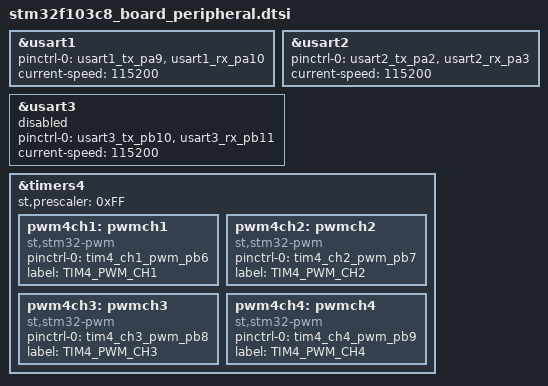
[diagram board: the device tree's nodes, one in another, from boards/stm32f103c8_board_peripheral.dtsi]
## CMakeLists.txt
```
# Author: Mohd Ramza <mohdramza@yahoo.com>
# SPDX-License-Identifier: Apache-2.0

cmake_minimum_required(VERSION 3.20.0)

set(BOARD_ROOT ${CMAKE_CURRENT_SOURCE_DIR})
set(BOARD com_f103c8)
set(CURR ${CMAKE_CURRENT_SOURCE_DIR})

list(APPEND DTC_OVERLAY_FILE ${CURR}/boards/stm32f103c8_board.overlay)
message(status ${DTC_OVERLAY_FILE})

# set(BOARD qemu_x86)
# set(BOARD_FLASH_RUNNER jlink)
find_package(Zephyr REQUIRED HINTS $ENV{ZEPHYR_BASE})
project(stm32f1_project)

# add top source files here
set(SOURCES src/main.c
)

# likely not need to add a .h include here as most modules will go into its own sub directory
set(INCLUDES)

target_include_directories(app PRIVATE ${INCLUDES})
target_sources(app PRIVATE ${SOURCES})

add_subdirectory(src/MANAGER/THREAD_MGR)
add_subdirectory(src/MANAGER/BLINK_MGR)

# Specific part for documentation sbuild. You should  provide -DBUILD_DOC=1 in CMake call to let it build documentation.
if(BUILD_DOC)
    include(doc/build_doxygen_documentation.cmake)
endif()
```

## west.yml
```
manifest:
  remotes:
    - name: zephyrproject-rtos
      url-base: https://github.com/zephyrproject-rtos
  projects:
    - name: zephyr
      remote: zephyrproject-rtos
      revision: zephyr-v3.1.0
      west-commands: scripts/west-commands.yml
      import:
        name-allowlist:
        - hal_st
        - hal_stm32
        - cmsis

  self:
    path: zephyr_stm32f1_minimal
```

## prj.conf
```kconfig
# CONFIG LOG
CONFIG_LOG=y
CONFIG_LOG_MODE_DEFERRED=y
CONFIG_LOG_MODE_OVERFLOW=y
CONFIG_LOG_SPEED=y

# CONFIG GPIO
CONFIG_GPIO=y

# CONFIG PWM
CONFIG_PWM=y
```

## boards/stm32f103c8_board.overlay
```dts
/*
 *	Author: Mohd Ramza <mohdramza@yahoo.com>
 *	SPDX-License-Identifier: Apache-2.0
 *	DTS FOR CUSTOM STM32F103C8 BOARD (BSP)
 */
#include "stm32f103c8_board_peripheral.dtsi"
#include "stm32f103c8_board_io_master.dtsi"


/**** New node additions to root ****/
/ {
	chosen {
		zephyr,console = &usart1; //logging
		zephyr,shell-uart = &usart1;
		zephyr,osdp-uart = &usart2;
	};
};
```

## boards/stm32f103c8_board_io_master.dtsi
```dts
/*
 *	Author: Mohd Ramza <mohdramza@yahoo.com>
 *	SPDX-License-Identifier: Apache-2.0
 *	list of the IO used in skycar
 */
/ {
	inputs_outputs:io {
		/* System state module */
		system_state_module {
			leds {
				compatible = "gpio-leds";
				blue_led: led_0 {
					gpios = <&gpioc 13 GPIO_ACTIVE_HIGH>;
					label = "User LD";
				};
			};
		};
	};
};
```

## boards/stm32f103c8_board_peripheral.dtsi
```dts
/* usart start */
&usart1 {
	pinctrl-0 = <&usart1_tx_pa9 &usart1_rx_pa10>;
	pinctrl-names = "default";
	current-speed = <115200>;
	status = "okay";
};

&usart2 {
	pinctrl-0 = <&usart2_tx_pa2 &usart2_rx_pa3>;
	pinctrl-names = "default";
	current-speed = <115200>;
	status = "okay";
};

&usart3 {
	pinctrl-0 = <&usart3_tx_pb10 &usart3_rx_pb11>;
	pinctrl-names = "default";
	current-speed = <115200>;
	status = "disabled";
};
/* usart end */

/* timer start */
&timers4 {
	status = "okay";
	st,prescaler = <0xFF>;

	// serving timers4 ch1 pwm
	pwm4ch1: pwmch1 {
		compatible = "st,stm32-pwm";
		status = "okay";
		pinctrl-0 = <&tim4_ch1_pwm_pb6>;
		pinctrl-names = "default";
		label = "TIM4_PWM_CH1";
		#pwm-cells = <3>;
	};

	// serving timers4 ch2 pwm
	pwm4ch2: pwmch2 {
		compatible = "st,stm32-pwm";
		status = "okay";
		pinctrl-0 = <&tim4_ch2_pwm_pb7>;
		pinctrl-names = "default";
		label = "TIM4_PWM_CH2";
		#pwm-cells = <3>;
	};

	// serving timers4 ch3 pwm
	pwm4ch3: pwmch3 {
		compatible = "st,stm32-pwm";
		status = "okay";
		pinctrl-0 = <&tim4_ch3_pwm_pb8>;
		pinctrl-names = "default";
		label = "TIM4_PWM_CH3";
		#pwm-cells = <3>;
	};

	// serving timers4 ch4 pwm
	pwm4ch4: pwmch4 {
		compatible = "st,stm32-pwm";
		status = "okay";
		pinctrl-0 = <&tim4_ch4_pwm_pb9>;
		pinctrl-names = "default";
		label = "TIM4_PWM_CH4";
		#pwm-cells = <3>;
	};
};
/* timer end */
```

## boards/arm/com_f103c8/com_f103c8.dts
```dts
/*
 * Copyright (c) 2017, embedjournal.com
 *
 * SPDX-License-Identifier: Apache-2.0
 */

/dts-v1/;
/*
 * Copyright (c) 2019, embedjournal.com
 *
 * SPDX-License-Identifier: Apache-2.0
 */

/dts-v1/;
#include <st/f1/stm32f103X8.dtsi>
#include <st/f1/stm32f103r(8-b)tx-pinctrl.dtsi>

/ {
	model = "STM32 Minimum Development Board";
	compatible = "st,stm32f103c8";

	chosen {
		zephyr,sram = &sram0;
		zephyr,flash = &flash0;
	};
};

&clk_hse {
	clock-frequency = <DT_FREQ_M(8)>;
	status = "okay";
};

&pll {
	mul = <9>;
	clocks = <&clk_hse>;
	status = "okay";
};

&rcc {
	clocks = <&pll>;
	clock-frequency = <DT_FREQ_M(72)>;
	ahb-prescaler = <1>;
	apb1-prescaler = <2>;
	apb2-prescaler = <1>;
};
```

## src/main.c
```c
/**
 * @file main.c
 * @brief Application entry point
 * @copyright 
 * @license Apache-2.0
 * @author Mohd Ramza <mohdramza@yahoo.com>
 */

#include <zephyr.h>
#include <kernel.h>
#include <logging/log.h>
#include "thread_manager.h"

LOG_MODULE_REGISTER(MAIN, LOG_LEVEL_INF);

/* A conditional variable to suspend main thread post initialization */
K_CONDVAR_DEFINE(main_thread_suspend_resume);
K_MUTEX_DEFINE(main_thread_mutex);

/**
 * @brief Entry point of application
 */
void main(void)
{
	LOG_INF("Hello. This is Stm32f1 Series Project");

	spawn_application_threads();

	while (1) {
		/*Lets suspend the thread as it has done its job*/
		LOG_WRN("Init done. Suspending myself!");
		k_condvar_wait(&main_thread_suspend_resume, &main_thread_mutex, K_FOREVER);
	}
}
```

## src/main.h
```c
/**
 * @file main.h
 * @brief Application entry point
 * @copyright 
 * @license Apache-2.0
 * @author Mohd Ramza <mohdramza@yahoo.com>
 */

#ifndef __MAIN_HEADER
#define __MAIN_HEADER

#endif
```
